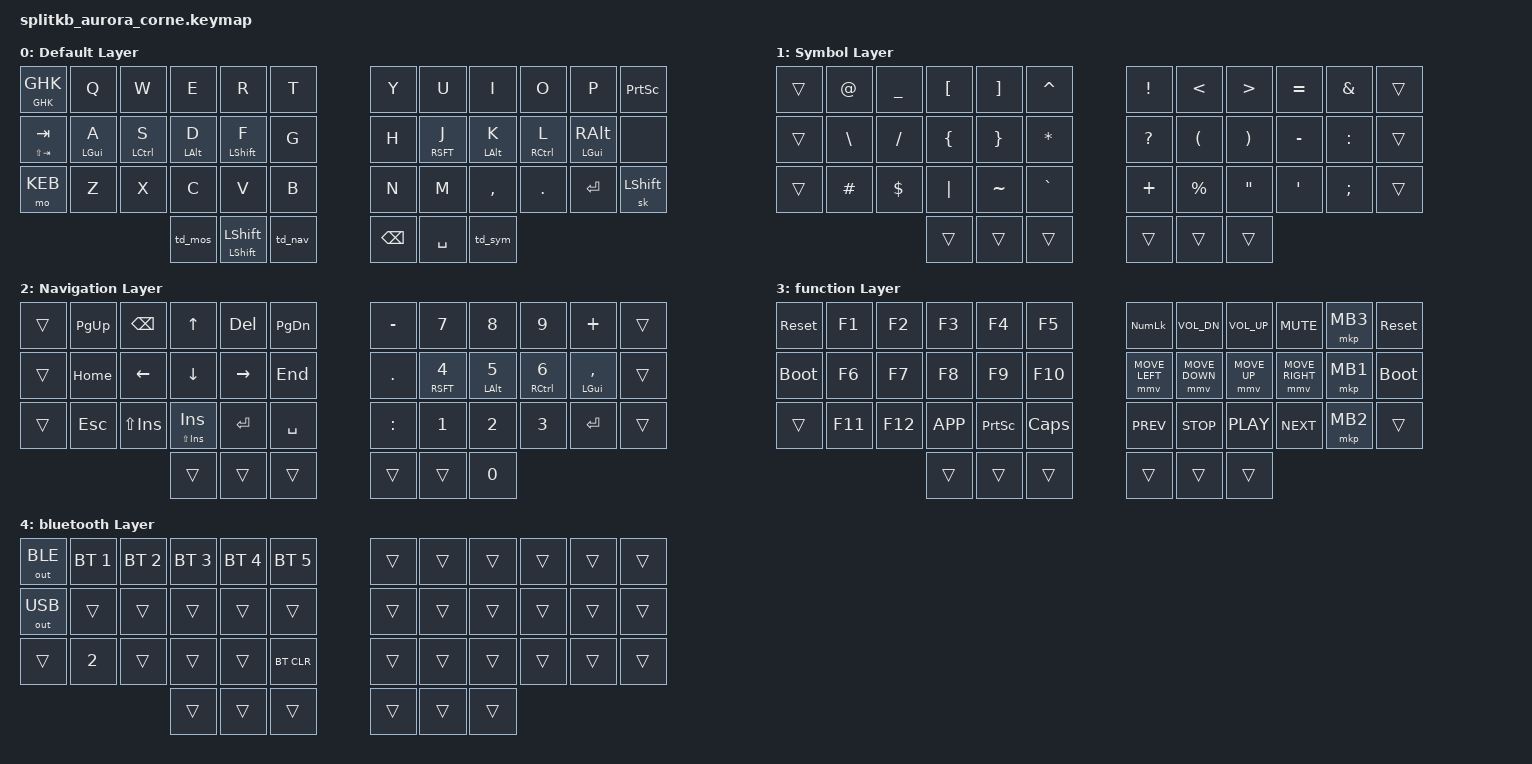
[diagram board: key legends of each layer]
/* Copyright (c) 2020 The ZMK Contributors
 *
 * SPDX-License-Identifier: MIT
 */

#include <behaviors.dtsi>
#include <dt-bindings/zmk/keys.h>
#include <dt-bindings/zmk/bt.h>
#include <dt-bindings/zmk/outputs.h>
#include <dt-bindings/zmk/pointing.h>

// TODO: tap-hold shift-insert
// TODO: make mouse work
// TODO: slh / sticky-layer is misbehaving

#define TAPPING_TERM <200>
#define TAPPING_TERM_SLOW <250>

#define SYM 1
#define NAV 2
#define MOS 3
#define KEB 4

#define GHK LG(LA(LCTRL))

/ {
	behaviors {
		mth: mod_tap_homerow {
			compatible = "zmk,behavior-hold-tap";
			#binding-cells = <2>;
			flavor = "tap-preferred";
			tapping-term-ms = TAPPING_TERM;
			quick-tap-ms = TAPPING_TERM;
			//require-prior-idle-ms = <100>
			bindings = <&kp>, <&kp>;
		};

		mtp: mod_tap_pinky {
			compatible = "zmk,behavior-hold-tap";
			#binding-cells = <2>;
			flavor = "tap-preferred";
			tapping-term-ms = TAPPING_TERM_SLOW;
			quick-tap-ms = TAPPING_TERM_SLOW;
			//require-prior-idle-ms = <100>
			bindings = <&kp>, <&kp>;
		};

		tog_on: toggle_on {
			compatible = "zmk,behavior-toggle-layer";
			#binding-cells = <1>;
			toggle-mode = "on";
		};

		tog_off: toggle_off {
			compatible = "zmk,behavior-toggle-layer";
			#binding-cells = <1>;
			toggle-mode = "off";
		};

		tog_hold: toggle_hold {
			compatible = "zmk,behavior-hold-tap";
			#binding-cells = <2>;
			flavor = "hold-preferred";
			tapping-term-ms = TAPPING_TERM;
			hold-while-undecided;
			bindings = <&mo>, <&tog_on>;
		};

		slh: sticky_layer_hold {
			compatible = "zmk,behavior-hold-tap";
			#binding-cells = <2>;
			flavor = "hold-preferred";
			tapping-term-ms = TAPPING_TERM;
			hold-while-undecided;
			bindings = <&mo>, <&sl>;
		};

		td_sym: tap_dance_sym {
			compatible = "zmk,behavior-tap-dance";
			#binding-cells = <0>;
			tapping-term-ms = TAPPING_TERM;
			bindings =
				//<&slh SYM SYM>, // TODO
				<&mo SYM>,
				<&tog_hold SYM SYM>,
				<&tog_off SYM>;
		};

		td_nav: tap_dance_nav {
			compatible = "zmk,behavior-tap-dance";
			#binding-cells = <0>;
			tapping-term-ms = TAPPING_TERM;
			bindings =
				//<&slh NAV NAV>, // TODO
				<&mo NAV>,
				<&tog_hold NAV NAV>,
				<&tog_off NAV>;
		};

		td_mos: tap_dance_mos {
			compatible = "zmk,behavior-tap-dance";
			#binding-cells = <0>;
			tapping-term-ms = TAPPING_TERM;
			bindings =
				//<&slh MOS MOS>, // TODO
				<&mo MOS>,
				<&tog_hold MOS MOS>,
				<&tog_off MOS>;
		};

		sh: sticky_hold {
			compatible = "zmk,behavior-hold-tap";
			#binding-cells = <2>;
			flavor = "hold-preferred";
			tapping-term-ms = <220>;
			hold-while-undecided;
			bindings = <&kp>, <&sk>;
		};

	};

	macros {
		s_ins: shift_insert { // unused
			compatible = "zmk,behavior-macro";
			#binding-cells = <0>;
			bindings =
				<&macro_press &kp LSHFT>,
				<&macro_tap &kp INS>,
				<&macro_release &kp LSHFT>;
		};

	};

        keymap {
                compatible = "zmk,keymap";

                default_layer { // 0
                        display-name = "Default Layer";
// -----------------------------------------------------------------------------------------
// | GHK  |  Q  |  W  |  E  |  R  |  T  |      |  Y  |  U   |  I  |  O  |  P    | PRINT |
// | TAB  |  A  |  S  |  D  |  F  |  G  |      |  H  |  J   |  K  |  L  |  RALT |       |
// |      |  Z  |  X  |  C  |  V  |  B  |      |  N  |  M   |  ,  |  .  |  RET  |       |
//                       | MOS |shift| NAV | |BSPC | SPACE| SYM |
                        bindings = <
   &sh GHK GHK      &kp Q        &kp W        &kp E       &kp R           &kp T       &kp Y    &kp U       &kp I        &kp O       &kp P          &kp PSCRN
   &mth LS(TAB) TAB &mtp LGUI A  &mth LCTRL S &mth LALT D &mth LSHFT F    &kp G       &kp H    &mth RSFT J &mth LALT K  &mth RCTL L &mth LGUI RALT &none
   &mo KEB          &kp Z        &kp X        &kp C       &kp V           &kp B       &kp N    &kp M       &kp COMMA    &kp DOT     &kp RET        &sk LSHFT
                                                &td_mos     &sh LSHFT LSHFT &td_nav &kp BSPC &kp SPACE   &td_sym
                        >;
                };

                symbol_layer { // 1
                        display-name = "Symbol Layer";
// -----------------------------------------------------------------------------------------
// |      |  @  |  _  |  [  |  ]  |  ^  |       |  !  |  <  |  >  |  =  |  &  |      |
// |      |  \  |  /  |  {  |  }  |  *  |       |  ?  |  (  |  )  |  -  |  :  |      |
// |      |  #  |  $  |  |  |  ~  |  `  |       |  +  |  %  |  "  |  '  |  ;  |      |
//                      |     |     |     |   |     |     |     |
                        bindings = <
   &trans &kp AT   &kp UNDER &kp LBKT &kp RBKT  &kp CARET    &kp EXCL  &kp LT    &kp GT    &kp EQUAL &kp AMPS &trans
   &trans &kp BSLH &kp FSLH  &kp LBRC &kp RBRC  &kp ASTRK    &kp QMARK &kp LPAR  &kp RPAR  &kp MINUS &kp COLON&trans
   &trans &kp HASH &kp DLLR  &kp PIPE &kp TILDE &kp GRAVE    &kp PLUS  &kp PRCNT &kp DQT   &kp SQT   &kp SEMI &trans
                               &trans   &trans    &trans   &trans    &trans    &trans
                        >;
                };

                nav_layer { // 2
                        display-name = "Navigation Layer";
// -----------------------------------------------------------------------------------------
// |      | PgUp| Bspc| up  | del  | PgDn|       |  -  |  7  |  8  |  9  |  +  |      |
// |      | Home| left| down| right| end |       |  .  |  4  |  5  |  6  |  ,  |      |
// |      | Esc | sIns| ins | ENT  | spac|       |  :  |  1  |  2  |  3  | ENT |      |
//                      |     |     |     |   |     |     |  0  |
                        bindings = <
   &trans &kp PG_UP &kp BSPC    &kp UP           &kp DEL   &kp PG_DN   &kp MINUS &kp N7       &kp N8       &kp N9       &kp PLUS        &trans
   &trans &kp HOME  &kp LEFT    &kp DOWN         &kp RIGHT &kp END     &kp DOT   &mth RSFT N4 &mth LALT N5 &mth RCTL N6 &mth LGUI COMMA &trans
   &trans &kp ESC   &kp LS(INS) &mth LS(INS) INS &kp RET   &kp SPACE   &kp COLON &kp N1       &kp N2       &kp N3       &kp RET         &trans
                                  &trans           &trans    &trans  &trans    &trans       &kp N0
                        >;
                };

		fn_layer { // 3
                        display-name = "function Layer";
// -----------------------------------------------------------------------------------------
// | RESET| F1  | F2  | F3  | F4   | F5  |       | num | VOLD| VOLU| MUTE|     | RESET|
// |      | F6  | F7  | F8  | F9   | F10 |       |     |     |     |     |     |      |
// |      | F11 | F11 | MENU| print| caps|       |mprev|mstop|mplay|mnext|     |      |
//                      |     |     |     |   |     |     |     |
                        bindings = <
   &sys_reset  &kp F1       &kp F2        &kp F3       &kp F4         &kp F5         &kp KP_NUM     &kp C_VOL_DN   &kp C_VOL_UP &kp C_MUTE      &mkp MB3 &sys_reset
   &bootloader &kp F6       &kp F7        &kp F8       &kp F9         &kp F10        &mmv MOVE_LEFT &mmv MOVE_DOWN &mmv MOVE_UP &mmv MOVE_RIGHT &mkp MB1 &bootloader
   &trans      &kp F11      &kp F12       &kp K_APP    &kp PSCRN      &kp CAPS       &kp C_PREV     &kp C_STOP     &kp C_PLAY   &kp C_NEXT      &mkp MB2 &trans
                                            &trans       &trans         &trans   &trans       &trans       &trans
                        >;
                };

		bt_layer { // 4
                        display-name = "bluetooth Layer";
// -----------------------------------------------------------------------------------------
// |      |     |     |    |    |     |       |     |     |     |     |     |      |
// |      |     |     |    |    |     |       |     |     |     |     |     |      |
// |      |     |     |    |    |     |       |     |     |     |     |     |      |
//                      |    |    |     |   |     |     |     |
                        bindings = <
   &out OUT_BLE &bt BT_SEL 1 &bt BT_SEL 2 &bt BT_SEL 3 &bt BT_SEL 4 &bt BT_SEL 5   &trans &trans &trans &trans &trans &trans
   &out OUT_USB &trans       &trans       &trans       &trans       &trans         &trans &trans &trans &trans &trans &trans
   &trans       &kp N2       &trans       &trans       &trans       &bt BT_CLR     &trans &trans &trans &trans &trans &trans
                                           &trans       &trans       &trans       &trans &trans &trans
                        >;
                };

        };
};
